# AON_BATMON register map
Vendor: Texas Instruments
Peripheral module from a debugger description file (folder CC26x0R2F).
Registers are 32-bit, access per field, reset 0x0 unless marked. A register's access mark holds for its fields unless they carry their own. Offsets are as the file gives them; lines under a group give offsets from that group; [hi:lo] are bit positions; {n}, {i} and the like mark numbered series; 'fields as' and 'values as' point back to an identical list; <NAME> marks a mode.

## AON_BATMON — Always On (AON) Battery And Temperature MONitor (BATMON) residing in the AON domain Note: This module only supports 32 bit Read/Write access from MCU.
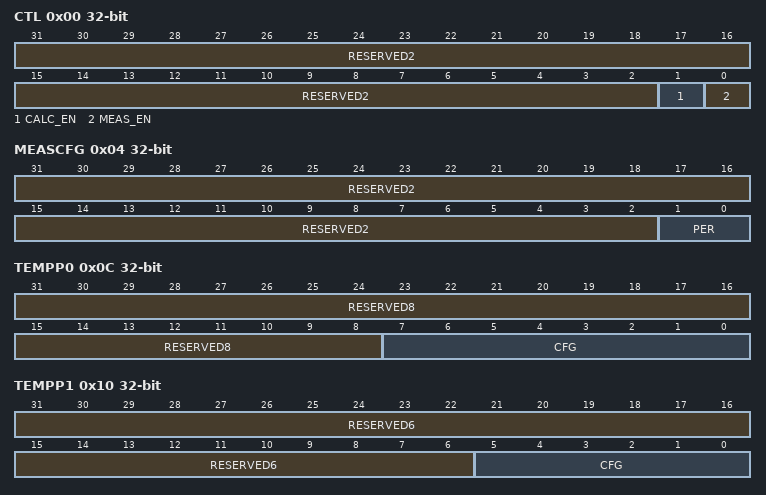
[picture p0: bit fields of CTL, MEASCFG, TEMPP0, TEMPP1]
0x00 CTL — Internal. Only to be used through TI provided API.
  [31:2] RESERVED2 ro — Internal. Only to be used through TI provided API.
  [1] CALC_EN rw — Internal. Only to be used through TI provided API.
  [0] MEAS_EN rw — Internal. Only to be used through TI provided API.
0x04 MEASCFG — Internal. Only to be used through TI provided API.
  [31:2] RESERVED2 ro — Internal. Only to be used through TI provided API.
  [1:0] PER rw — Internal. Only to be used through TI provided API.
    3=32CYC (Internal. Only to be used through TI provided API.); 2=16CYC (Internal. Only to be used through TI provided API.); 1=8CYC (Internal. Only to be used through TI provided API.); 0=CONT (Internal. Only to be used through TI provided API.)
0x0C TEMPP0 — Internal. Only to be used through TI provided API.
  [31:8] RESERVED8 ro — Internal. Only to be used through TI provided API.
  [7:0] CFG rw — Internal. Only to be used through TI provided API.
0x10 TEMPP1 — Internal. Only to be used through TI provided API.
  [31:6] RESERVED6 ro — Internal. Only to be used through TI provided API.
  [5:0] CFG rw — Internal. Only to be used through TI provided API.
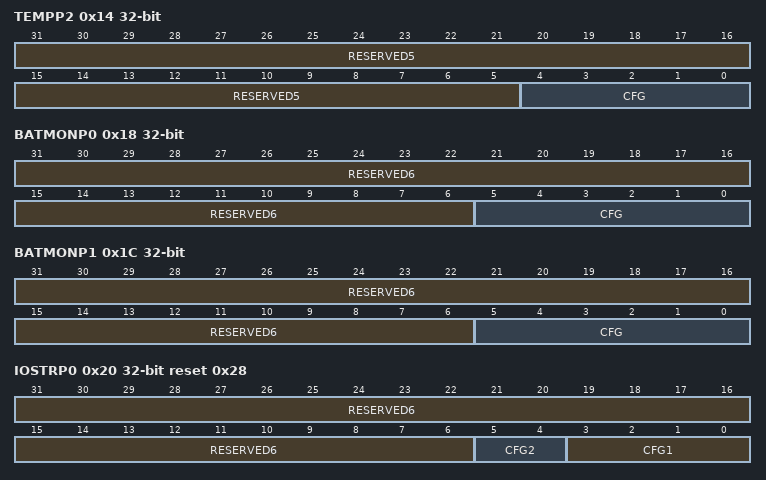
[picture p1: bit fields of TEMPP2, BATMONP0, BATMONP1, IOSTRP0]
0x14 TEMPP2 — Internal. Only to be used through TI provided API.
  [31:5] RESERVED5 ro — Internal. Only to be used through TI provided API.
  [4:0] CFG rw — Internal. Only to be used through TI provided API.
0x18 BATMONP0 — Internal. Only to be used through TI provided API.
  fields as TEMPP1
0x1C BATMONP1 — Internal. Only to be used through TI provided API.
  fields as TEMPP1
0x20 IOSTRP0 reset 0x28 — Internal. Only to be used through TI provided API.
  [31:6] RESERVED6 ro — Internal. Only to be used through TI provided API.
  [5:4] CFG2 rw — Internal. Only to be used through TI provided API.
  [3:0] CFG1 rw — Internal. Only to be used through TI provided API.
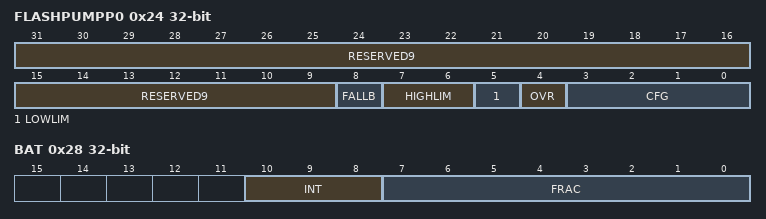
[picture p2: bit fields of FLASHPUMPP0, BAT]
0x24 FLASHPUMPP0 — Internal. Only to be used through TI provided API.
  [31:9] RESERVED9 ro — Internal. Only to be used through TI provided API.
  [8] FALLB rw — Internal. Only to be used through TI provided API.
  [7:6] HIGHLIM rw — Internal. Only to be used through TI provided API.
  [5] LOWLIM rw — Internal. Only to be used through TI provided API.
  [4] OVR rw — Internal. Only to be used through TI provided API.
  [3:0] CFG rw — Internal. Only to be used through TI provided API.
0x28 BAT ro — Last Measured Battery Voltage This register may be read while BATUPD.STAT = 1
  [10:8] INT — Integer part: 0x0: 0V + fractional part ... 0x3: 3V + fractional part 0x4: 4V + fractional part
  [7:0] FRAC — Fractional part, standard binary fractional encoding. 0x00: .0V ... 0x20: 1/8 = .125V 0x40: 1/4 = .25V 0x80: 1/2 = .5V ... 0xA0: 1/2 + 1/8 = .625V ... 0xFF: Max
0x2C BATUPD — Battery Update Indicates BAT Updates
  [0] STAT rw — 0: No update since last clear 1: New battery voltage is present. Write 1 to clear the status.
0x30 TEMP ro — Temperature Last Measured Temperature in Degrees Celsius This register may be read while TEMPUPD.STAT = 1.
  [16:8] INT — Integer part (signed) of temperature value. Total value = INTEGER + FRACTIONAL 2's complement encoding 0x100: Min value 0x1D8: -40C 0x1FF: -1C 0x00: 0C 0x1B: 27C 0x55: 85C 0xFF: Max value
0x34 TEMPUPD — Temperature Update Indicates TEMP Updates
  [0] STAT rw — 0: No update since last clear 1: New temperature is present. Write 1 to clear the status.
